# MIMXRT685S_cm33 register map
Vendor: nxp.com; File version: 1.0
CPU: CM33 r2p0, little endian, MPU, FPU, VTOR, 3 interrupt priority bits
Registers are 32-bit, read-write, reset 0x0 unless marked. A register's access mark holds for its fields unless they carry their own. Offsets are from the block's base; [hi:lo] are bit positions; {n}, {i} and the like mark numbered series; 'fields as' and 'values as' point back to an identical list.

## IOPCTL — LPC-Next0 IO pad controller
Base 0x40004000
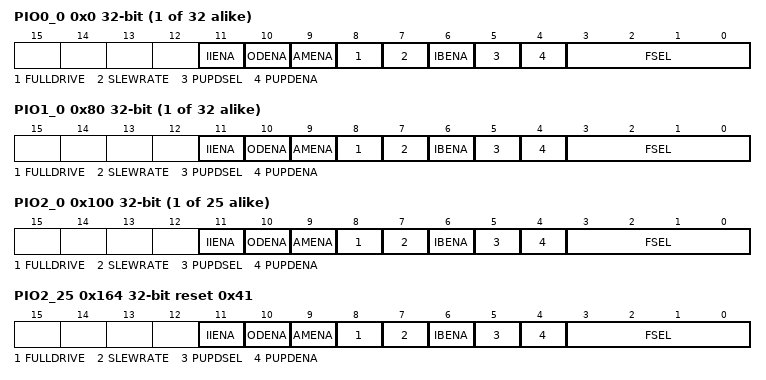
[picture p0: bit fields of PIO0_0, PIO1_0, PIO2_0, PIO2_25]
{0x0+4i} PIO0_{i} (i=0..31) — iop pad control register for port0 to port5
  [11] IIENA — Input Invert Enable. . .
    0=DISABLED; 1=ENABLED
  [10] ODENA — Pseudo Output Drain Enable. . .
    0=DISABLED; 1=ENABLED
  [9] AMENA — Analog Mux Enable. . .
    0=DISABLED; 1=ENABLED
  [8] FULLDRIVE — Drive Selector. . .
    0=NORMAL_DRIVE; 1=FULL_DRIVE
  [7] SLEWRATE — Slew Rate Control. . .
    0=NORMAL (Slew Rate is Normal.); 1=SLOW (Slew Rate Slow.)
  [6] IBENA — Input Buffer Enable. .
    0=DISABLED; 1=ENABLED
  [5] PUPDSEL — Pullup or Pulldown Selector. . .
    0=PULL_DOWN; 1=PULL_UP
  [4] PUPDENA — Pullup / Pulldown Enable. . .
    0=DISABLED; 1=ENABLED
  [3:0] FSEL — Function Selector. . .(FSELs Sources can be found in the next several pages.)
    {v}=FUNCTION_{v} (v=0..15)
{0x80+4i} PIO1_{i} (i=0..31) — iop pad control register for port0 to port5
  fields as PIO0_0
{0x100+4i} PIO2_{i} (i=0..24) — iop pad control register for port0 to port5
  fields as PIO0_0
0x164 PIO2_25 reset 0x41 — iop pad control register for port0 to port5
  fields as PIO0_0
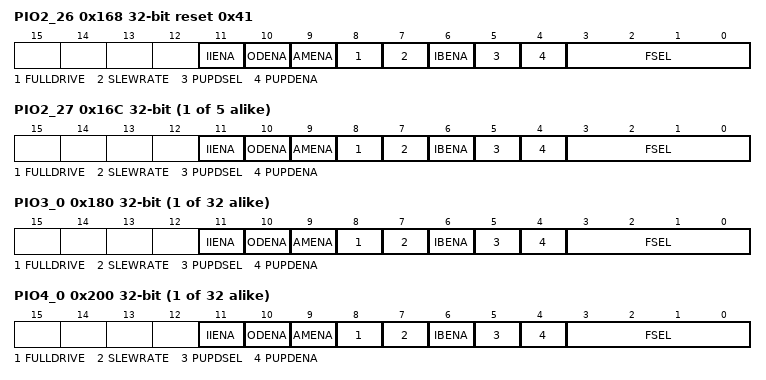
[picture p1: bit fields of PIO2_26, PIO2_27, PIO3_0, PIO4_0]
0x168 PIO2_26 reset 0x41 — iop pad control register for port0 to port5
  fields as PIO0_0
{0x100+4i} PIO2_{i} (i=27..31) — iop pad control register for port0 to port5
  fields as PIO0_0
{0x180+4i} PIO3_{i} (i=0..31) — iop pad control register for port0 to port5
  fields as PIO0_0
{0x200+4i} PIO4_{i} (i=0..31) — iop pad control register for port0 to port5
  fields as PIO0_0
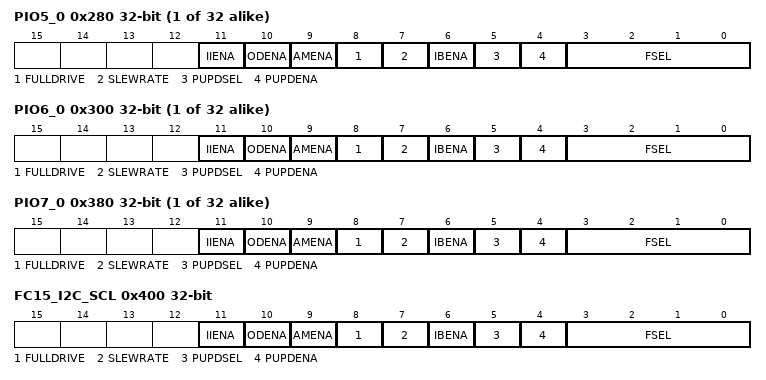
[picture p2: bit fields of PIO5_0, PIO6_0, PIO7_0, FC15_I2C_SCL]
{0x280+4i} PIO5_{i} (i=0..31) — iop pad control register for port0 to port5
  fields as PIO0_0
{0x300+4i} PIO6_{i} (i=0..31) — iop pad control register for port0 to port5
  fields as PIO0_0
{0x380+4i} PIO7_{i} (i=0..31) — iop pad control register for port0 to port5
  fields as PIO0_0
0x400 FC15_I2C_SCL — Special Registers (No GPIO Function)
  fields as PIO0_0
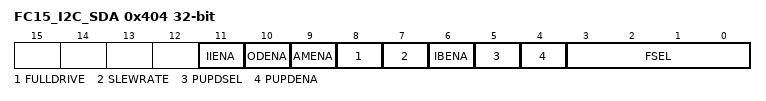
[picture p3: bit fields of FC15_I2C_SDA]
0x404 FC15_I2C_SDA — Special Registers (No GPIO Function)
  fields as PIO0_0

## WWDT0 — LPC_Next0 Windowed Watchdog Timer (WWDT)
Base 0x4000E000
Same registers: WWDT1 0x4002E000
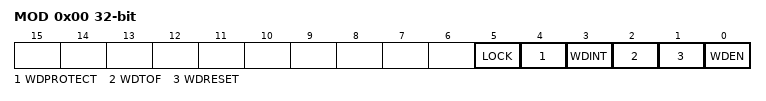
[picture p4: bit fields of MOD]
0x00 MOD — Watchdog mode register. This register contains the basic mode and status of the Watchdog Timer.
  [5] LOCK — Once this bit is set to one and a watchdog feed is performed, disabling or powering down the watchdog oscillator is prevented by hardware. This bit can be set once by software and is only cleared by any reset.
  [4] WDPROTECT — Watchdog update mode. This bit can be set once by software and is only cleared by a reset.
    0=FLEXIBLE (Flexible. The watchdog time-out value (TC) can be changed at any time.); 1=THRESHOLD (Threshold. The watchdog time-out value (TC) can be changed only after the counter is below the value of WDWARNINT and WDWINDOW.)
  [3] WDINT — Warning interrupt flag. Set when the timer is at or below the value in WDWARNINT. Cleared by software writing a 1 to this bit position. Note that this bit cannot be cleared while the WARNINT value is equal to the value of the TV register. This can occur if the value of WARNINT is 0 and the WDRESET bit is 0 when TV decrements to 0.
  [2] WDTOF — Watchdog time-out flag. Set when the watchdog timer times out, by a feed error, or by events associated with WDPROTECT. Cleared by software writing a 0 to this bit position. Causes a chip reset if WDRESET = 1.
  [1] WDRESET — Watchdog reset enable bit. Once this bit has been written with a 1 it cannot be re-written with a 0.
    0=INTERRUPT (Interrupt. A watchdog time-out will not cause a chip reset.); 1=RESET (Reset. A watchdog time-out will cause a chip reset.)
  [0] WDEN — Watchdog enable bit. Once this bit is set to one and a watchdog feed is performed, the watchdog timer will run permanently.
    0=STOP (Stop. The watchdog timer is stopped.); 1=RUN (Run. The watchdog timer is running.)
0x04 TC reset 0xFF — Watchdog timer constant register. This 24-bit register determines the time-out value.
  [23:0] COUNT — Watchdog time-out value.
0x08 FEED wo reset not defined — Watchdog feed sequence register. Writing 0xAA followed by 0x55 to this register reloads the Watchdog timer with the value contained in TC.
  [7:0] FEED — Feed value should be 0xAA followed by 0x55.
0x0C TV ro reset 0xFF — Watchdog timer value register. This 24-bit register reads out the current value of the Watchdog timer.
  [23:0] COUNT — Counter timer value.
0x14 WARNINT — Watchdog Warning Interrupt compare value.
  [9:0] WARNINT — Watchdog warning interrupt compare value.
0x18 WINDOW reset 0xFFFFFF — Watchdog Window compare value.
  [23:0] WINDOW — Watchdog window value.
